# FM33FK5XX register map
File version: 1.0
CPU: Cortex-M33 r1p0, little endian, MPU, FPU, 3 interrupt priority bits
Registers are 32-bit, read-write, reset 0x0 unless marked. A register's access mark holds for its fields unless they carry their own. Offsets are from the block's base; [hi:lo] are bit positions.

## I2CSMB0 — I2CSMB0 module information
Base 0x40015800
Same registers: I2CSMB2 0x40014C00, I2CSMB1 0x40015C00
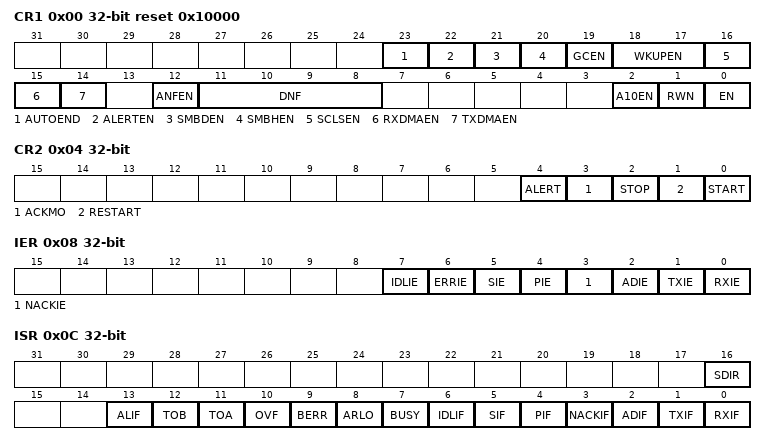
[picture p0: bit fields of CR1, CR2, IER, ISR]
0x00 CR1 reset 0x10000 — I2CSMBusControlRegister
  [23] AUTOEND — AUTOEND field description
  [22] ALERTEN — ALERTEN field description
  [21] SMBDEN — SMBDEN field description
  [20] SMBHEN — SMBHEN field description
  [19] GCEN — GCEN field description
  [18:17] WKUPEN — WKUPEN field description
  [16] SCLSEN — SCLSEN field description
  [15] RXDMAEN — RXDMAEN field description
  [14] TXDMAEN — TXDMAEN field description
  [12] ANFEN — ANFEN field description
  [11:8] DNF — DNF field description
  [2] A10EN — A10EN field description
  [1] RWN — RWN field description
  [0] EN — EN field description
0x04 CR2 — I2CSMBusControlRegister
  [4] ALERT — ALERT field description
  [3] ACKMO — ACKMO field description
  [2] STOP — STOP field description
  [1] RESTART — RESTART field description
  [0] START — START field description
0x08 IER — I2CSMBusIntteruptEnableRegister
  [7] IDLIE — IDLIE field description
  [6] ERRIE — ERRIE field description
  [5] SIE — SIE field description
  [4] PIE — PIE field description
  [3] NACKIE — NACKIE field description
  [2] ADIE — ADIE field description
  [1] TXIE — TXIE field description
  [0] RXIE — RXIE field description
0x0C ISR access per field — I2CMasterInterruptStatusRegister
  [16] SDIR ro — SDIR field description
  [13] ALIF rw — ALIF field description
  [12] TOB rw — TOB field description
  [11] TOA rw — TOA field description
  [10] OVF rw — OVF field description
  [9] BERR rw — BERR field description
  [8] ARLO rw — ARLO field description
  [7] BUSY ro — BUSY field description
  [6] IDLIF rw — IDLIF field description
  [5] SIF rw — SIF field description
  [4] PIF rw — PIF field description
  [3] NACKIF rw — NACKIF field description
  [2] ADIF rw — ADIF field description
  [1] TXIF rw — TXIF field description
  [0] RXIF rw — RXIF field description
0x14 TCR
  [8:0] SDAHD — SDAHD field description
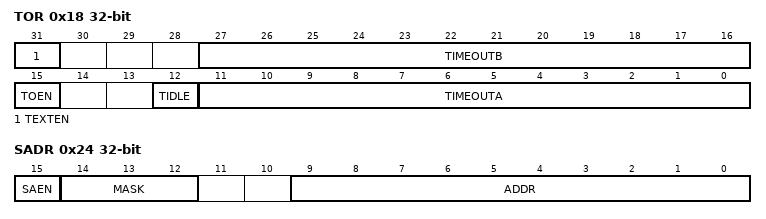
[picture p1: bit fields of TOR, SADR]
0x18 TOR
  [31] TEXTEN — TEXTEN field description
  [27:16] TIMEOUTB — TIMEOUTB field description
  [15] TOEN — TOEN field description
  [12] TIDLE — TIDLE field description
  [11:0] TIMEOUTA — TIMEOUTA field description
0x24 SADR
  [15] SAEN — SAEN field description
  [14:12] MASK — MASK field description
  [9:0] ADDR — ADDR field description
0x28 CRCDR ro reset 0xFF
  [7:0] DR — DR field description
0x2C CRCLFSR reset 0xFF
  [7:0] LFSR — LFSR field description
0x30 CRCPOLY reset 0x7
  [7:0] POLY — POLY field description

## I2C0 — I2C0 module information
Base 0x40015000
Same registers: I2C1 0x40015400
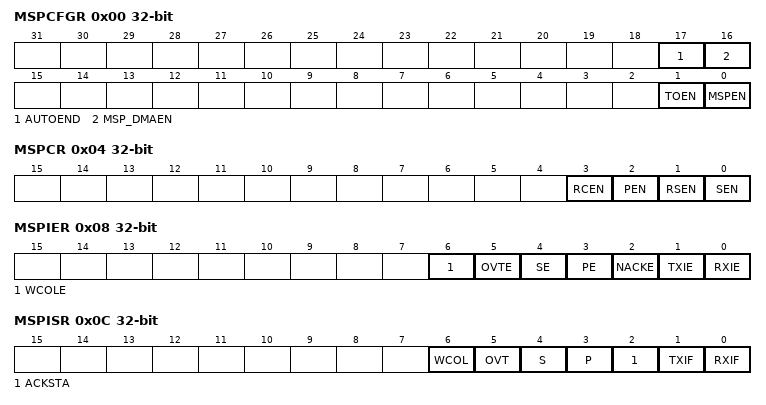
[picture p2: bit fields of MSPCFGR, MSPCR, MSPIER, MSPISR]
0x00 MSPCFGR — I2CMasterConfigRegister
  [17] AUTOEND — AUTOEND field description
  [16] MSP_DMAEN — MSP_DMAEN field description
  [1] TOEN — TOEN field description
  [0] MSPEN — MSPEN field description
0x04 MSPCR — I2CMasterControlRegister
  [3] RCEN — RCEN field description
  [2] PEN — PEN field description
  [1] RSEN — RSEN field description
  [0] SEN — SEN field description
0x08 MSPIER — I2CMasterIntteruptEnableRegister
  [6] WCOLE — WCOLE field description
  [5] OVTE — OVTE field description
  [4] SE — SE field description
  [3] PE — PE field description
  [2] NACKE — NACKE field description
  [1] TXIE — TXIE field description
  [0] RXIE — RXIE field description
0x0C MSPISR access per field — I2CMasterInterruptStatusRegister
  [6] WCOL rw — WCOL field description
  [5] OVT rw — OVT field description
  [4] S ro — S field description
  [3] P ro — P field description
  [2] ACKSTA rw — ACKSTA field description
  [1] TXIF rw — TXIF field description
  [0] RXIF rw — RXIF field description
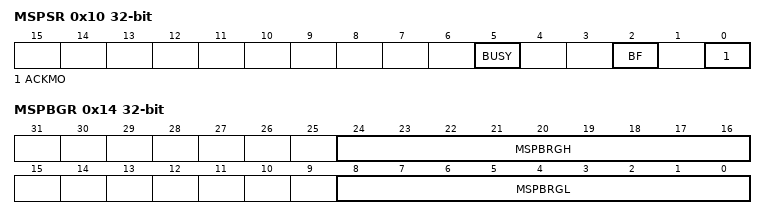
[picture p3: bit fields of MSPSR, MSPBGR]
0x10 MSPSR access per field — I2CMasterStatusRegister
  [5] BUSY ro — BUSY field description
  [2] BF ro — BF field description
  [0] ACKMO rw — ACKMO field description
0x14 MSPBGR — I2CMasterBaudrateGeneratorRegister
  [24:16] MSPBRGH — MSPBRGH field description
  [8:0] MSPBRGL — MSPBRGL field description
0x18 MSPBUF — I2CMastertransferBuffer
  [7:0] MSPBUF — MSPBUF field description
0x1C MSPTCR — I2CMasterTimingControlRegister
  [8:0] SDAHD — SDAHD field description
0x20 MSPTOR reset 0xFFF — I2CMasterTime-OutRegister
  [11:0] TIMEOUT — TIMEOUT field description
